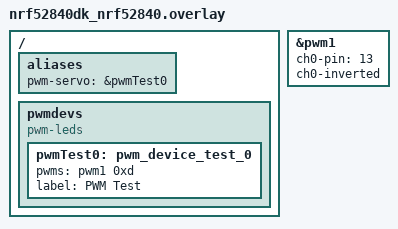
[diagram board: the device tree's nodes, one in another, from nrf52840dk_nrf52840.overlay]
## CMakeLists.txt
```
#
# Copyright (c) 2019 Nordic Semiconductor ASA
#
# SPDX-License-Identifier: LicenseRef-BSD-5-Clause-Nordic
#
cmake_minimum_required(VERSION 3.8.2)

#Board selection
set(BOARD nrf52840dk_nrf52840)
#set(BOARD nrf5340pdk_nrf5340_cpunet)
#set(BOARD nrf5340pdk_nrf5340_cpuapp)
#set(BOARD nrf52840dongle_nrf52840)
#set(BOARD nrf52840dk_nrf52811)

find_package(Zephyr REQUIRED HINTS $ENV{ZEPHYR_BASE})
project(NONE)

# Include all files in folder src
FILE(GLOB app_sources_c src/*.c)
FILE(GLOB app_sources_cpp src/*.cpp)


target_sources(app PRIVATE
	${app_sources_c}
	${app_sources_cpp})
target_include_directories(app PRIVATE include)
```

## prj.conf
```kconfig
#
# Copyright (c) 2019 Nordic Semiconductor ASA
#
# SPDX-License-Identifier: LicenseRef-BSD-5-Clause-Nordic
#
CONFIG_NCS_SAMPLES_DEFAULTS=y

# General configuration
CONFIG_SYSTEM_WORKQUEUE_STACK_SIZE=2048
CONFIG_FLASH=y
CONFIG_FLASH_MAP=y
CONFIG_FCB=y
CONFIG_SETTINGS=y
CONFIG_HWINFO=y
CONFIG_LOG=y
CONFIG_LOG_PRINTK=y

CONFIG_DK_LIBRARY=y
CONFIG_BT_MESH_DK_PROV=y

# Bluetooth configuration
CONFIG_BT=y
CONFIG_BT_COMPANY_ID=0x0059
CONFIG_BT_DEVICE_NAME="Servo Valve"
CONFIG_BT_L2CAP_TX_MTU=69
CONFIG_BT_L2CAP_TX_BUF_COUNT=8
CONFIG_BT_LL_SW_SPLIT=y
CONFIG_BT_OBSERVER=y
CONFIG_BT_PERIPHERAL=y
CONFIG_BT_SETTINGS=y
CONFIG_BT_MAX_CONN=3

# Disable unused Bluetooth features
CONFIG_BT_CTLR_DUP_FILTER_LEN=0
CONFIG_BT_CTLR_LE_ENC=n
CONFIG_BT_DATA_LEN_UPDATE=n
CONFIG_BT_PHY_UPDATE=n
CONFIG_BT_CTLR_CHAN_SEL_2=n
CONFIG_BT_CTLR_MIN_USED_CHAN=n
CONFIG_BT_CTLR_PRIVACY=n

# Bluetooth Mesh configuration standrad node configuration
CONFIG_BT_MESH=y
CONFIG_BT_MESH_ADV_BUF_COUNT=13
CONFIG_BT_MESH_TX_SEG_MAX=10
CONFIG_BT_MESH_PB_GATT=y
# Bluetooth Mesh Node Features Normal
CONFIG_BT_MESH_RELAY=y
CONFIG_BT_MESH_FRIEND=n
CONFIG_BT_MESH_FRIEND_LPN_COUNT=10
CONFIG_BT_MESH_GATT_PROXY=y
# Bluetooth Mesh Node Features LPN
#CONFIG_BT_MESH_RELAY=n
#CONFIG_BT_MESH_FRIEND=n
#CONFIG_BT_MESH_LOW_POWER=y
#CONFIG_BT_MESH_LPN_AUTO=y
#CONFIG_BT_MESH_LPN_AUTO_TIMEOUT=5
#600 = 60s
#CONFIG_BT_MESH_LPN_POLL_TIMEOUT=600
#CONFIG_BT_MESH_GATT_PROXY=n
# Power Managment Device -> Needed for LPN
#CONFIG_PM=y
#CONFIG_PM_DEVICE=y
#CONFIG_PM_DEVICE_RUNTIME=y
#CONFIG_PM_CPU_OPS=y
#CONFIG_SERIAL=n

# Bluetooth Mesh models
CONFIG_BT_MESH_ONOFF_SRV=y

# Servos PWM
CONFIG_PWM=y
CONFIG_PWM_LOG_LEVEL_DBG=y

#For Reset
CONFIG_REBOOT=y

#For nRF52 Dongle (enable if flashed over USB / Disable if FLashed over SWD)
CONFIG_BOARD_HAS_NRF5_BOOTLOADER=y
```

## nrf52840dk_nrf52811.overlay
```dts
/ {
     aliases {
             pwm-servo = &pwm0;
     };
};
```

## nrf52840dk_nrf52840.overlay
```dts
/ {
     aliases {
             pwm-servo = &pwmTest0;
     };
};

&pwm1 {
  status = "okay";
  ch0-pin = <13>;
  ch0-inverted;
 };

/ {
	pwmdevs {
		compatible = "pwm-leds";
		pwmTest0: pwm_device_test_0 {
			pwms = < &pwm1 0xd >;
			label = "PWM Test";
		};
	};
};
```

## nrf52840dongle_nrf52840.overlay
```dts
/ {
     aliases {
             pwm-servo = &pwmTest0;
     };
};

&pwm1 {
  status = "okay";
  ch0-pin = <15>;
  ch0-inverted;
 };

/ {
	pwmdevs {
		compatible = "pwm-leds";
		pwmTest0: pwm_device_test_0 {
			pwms = < &pwm1 0xf >;
			label = "PWM Test";
		};
	};
};
```

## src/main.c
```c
#include "bm_blemesh.h"
#include "bm_simple_buttons_and_leds.h"
#include <zephyr.h>
#include <bm_servo_valve.h>
#include <sys/reboot.h>



void reset(){
  printk("Reboot now!\n");
  sys_reboot(SYS_REBOOT_COLD);
}


/**@brief Function for application main entry.
 */
void main(void) {
  // Start Application
  printk("Starting Application...\n");
  // Init MAC Address
  uint32_t LSB_MAC_Address = NRF_FICR->DEVICEADDR[0];
  printk("Preprogrammed Randomly Static MAC-Address (LSB): 0x%x, %u \n", LSB_MAC_Address, LSB_MAC_Address);
  // Init Leds
  bm_init_leds();
  //Init Reset Buttons
  bm_init_buttons(reset);
  // Start Mesh Operation
  bm_blemesh_enable(); // Will return faster than the Stack is realy ready... keep on waiting in the transition.

  bm_init_servo();

}
```

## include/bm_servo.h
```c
#ifndef BM_SERVO_H
#define BM_SERVO_H

void bm_init_servo(void);

void do_test(void);


#endif
```

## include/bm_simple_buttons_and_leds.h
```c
/*
This file is part of Benchamrk-Shared-Library.

Benchamrk-Shared-Library is free software: you can redistribute it and/or modify
it under the terms of the GNU General Public License as published by
the Free Software Foundation, either version 3 of the License, or
(at your option) any later version.

Benchamrk-Shared-Library is distributed in the hope that it will be useful,
but WITHOUT ANY WARRANTY; without even the implied warranty of
MERCHANTABILITY or FITNESS FOR A PARTICULAR PURPOSE.  See the
GNU General Public License for more details.

You should have received a copy of the GNU General Public License
along with Benchamrk-Shared-Library.  If not, see <http://www.gnu.org/licenses/>.
*/

/* AUTHOR ZEPHYR_BLE_MESH  :   Raffael Anklin        */
/* AUTHOR NRF_SDK_ZIGBEE   :   Cyrill Horath        */


#ifdef __cplusplus
extern "C" {
#endif

#ifndef SIMPLE_BUTTONS_AND_LEDS_H
#define SIMPLE_BUTTONS_AND_LEDS_H


#include <zephyr.h>
#include <device.h>
#include <devicetree.h>
#include <devicetree_unfixed.h>
#include <drivers/gpio.h>
#include <sys/util.h>
#include <sys/slist.h>

/*
 * Devicetree helper macro which gets the 'flags' cell from a 'gpios'
 * property, or returns 0 if the property has no 'flags' cell.
 */

#define FLAGS_OR_ZERO(node)						\
	COND_CODE_1(DT_PHA_HAS_CELL(node, gpios, flags),		\
		    (DT_GPIO_FLAGS(node, gpios)),			\
		    (0))



/* The devicetree node identifier for the "led0" alias. */
#define LED0_NODE DT_ALIAS(led0)

#if DT_NODE_HAS_STATUS(LED0_NODE, okay)
#define LED0	DT_GPIO_LABEL(LED0_NODE, gpios)
#define PIN_LED0	DT_GPIO_PIN(LED0_NODE, gpios)
#if DT_PHA_HAS_CELL(LED0_NODE, gpios, flags)
#define FLAGS_LED0	DT_GPIO_FLAGS(LED0_NODE, gpios)
#endif
#else
/* A build error here means your board isn't set up to blink an LED. */
#error "Unsupported board: led0 devicetree alias is not defined"
#define LED0	""
#define PIN_LED0	0
#endif

#ifndef FLAGS_LED0
#define FLAGS_LED0	0
#endif

/* The devicetree node identifier for the "led1" alias. Is the RED LED on THe nRF52 Donlge*/
#define LED1_NODE DT_ALIAS(led1)

#if DT_NODE_HAS_STATUS(LED1_NODE, okay)
#define LED1	DT_GPIO_LABEL(LED1_NODE, gpios)
#define PIN_LED1	DT_GPIO_PIN(LED1_NODE, gpios)
#if DT_PHA_HAS_CELL(LED1_NODE, gpios, flags)
#define FLAGS_LED1	DT_GPIO_FLAGS(LED1_NODE, gpios)
#endif
#else
/* A build error here means your board isn't set up to blink an LED. */
#error "Unsupported board: led1 devicetree alias is not defined"
#define LED1	""
#define PIN_LED1	0
#endif

#ifndef FLAGS_LED1
#define FLAGS_LED1	0
#endif


/* The devicetree node identifier for the "led2" alias. Is the GREEN LED on THe nRF52 Donlge*/
#define LED2_NODE DT_ALIAS(led2)

#if DT_NODE_HAS_STATUS(LED2_NODE, okay)
#define LED2	DT_GPIO_LABEL(LED2_NODE, gpios)
#define PIN_LED2	DT_GPIO_PIN(LED2_NODE, gpios)
#if DT_PHA_HAS_CELL(LED2_NODE, gpios, flags)
#define FLAGS_LED2	DT_GPIO_FLAGS(LED2_NODE, gpios)
#endif
#else
/* A build error here means your board isn't set up to blink an LED. */
#error "Unsupported board: led2 devicetree alias is not defined"
#define LED2	""
#define PIN_LED2	0
#endif

#ifndef FLAGS_LED2
#define FLAGS_LED1	0
#endif

/* The devicetree node identifier for the "led3" alias. Is the BLUE LED on THe nRF52 Donlge*/
#define LED3_NODE DT_ALIAS(led3)

#if DT_NODE_HAS_STATUS(LED3_NODE, okay)
#define LED3	DT_GPIO_LABEL(LED3_NODE, gpios)
#define PIN_LED3	DT_GPIO_PIN(LED3_NODE, gpios)
#if DT_PHA_HAS_CELL(LED3_NODE, gpios, flags)
#define FLAGS_LED3	DT_GPIO_FLAGS(LED3_NODE, gpios)
#endif
#else
/* A build error here means your board isn't set up to blink an LED. */
#error "Unsupported board: led3 devicetree alias is not defined"
#define LED3	""
#define PIN_LED3	0
#endif

#ifndef FLAGS_LED3
#define FLAGS_LED3	0
#endif


/*
 * Get button configuration from the devicetree sw0 alias.
 *
 * At least a GPIO device and pin number must be provided. The 'flags'
 * cell is optional.
 */

#define SW0_NODE	DT_ALIAS(sw0)

#if DT_NODE_HAS_STATUS(SW0_NODE, okay)
#define SW0_GPIO_LABEL	DT_GPIO_LABEL(SW0_NODE, gpios)
#define SW0_GPIO_PIN	DT_GPIO_PIN(SW0_NODE, gpios)
#define SW0_GPIO_FLAGS	(GPIO_INPUT | FLAGS_OR_ZERO(SW0_NODE) | GPIO_INT_DEBOUNCE)
#else
#error "Unsupported board: sw0 devicetree alias is not defined"
#define SW0_GPIO_LABEL	""
#define SW0_GPIO_PIN	0
#define SW0_GPIO_FLAGS	0
#endif




/**
* Init the Buttons
*
*/
void bm_init_buttons(void (*button0_cb)());



/**
* Get the BUTTON0 Toggled State
*
* @return State of the BUTTON0 Toggled State (0/1)
*/
bool bm_button0_toggle_state_get();

/**
* Set the BUTTON0 Toggled State
*
* @param State of the BUTTON0 Toggled State (0/1)
*/
void bm_button0_toggle_state_set(bool newstate);



/**
* Init the Leds
*
*/
void bm_init_leds();

/**
* Set the LED0 State
*
* @param State to set the LED0 to (0/1) (GREEN no RGB on nRF52 Dongle / LED1 on nRF52 DK)
*/
void bm_led0_set(bool state);

/**
* Get the LED0 State
*
* @return State of the LED0 (0/1) (GREEN no RGB on nRF52 Dongle / LED1 on nRF52 DK)
*/
bool bm_led0_get();


/**
* Set the LED1 State
*
* @param State to set the LED1 to (0/1) (RED on nRF52 Dongle / LED2 on nRF52 DK)
*/
void bm_led1_set(bool state);

/**
* Get the LED1 State
*
* @return State of the LED1 (0/1) (RED on nRF52 Dongle / LED2 on nRF52 DK)
*/
bool bm_led1_get();

/**
* Set the LED2 State
*
* @param State to set the LED2 to (0/1) (GREEN on nRF52 Dongle / LED3 on nRF52 DK)
*/
void bm_led2_set(bool state);

/**
* Get the LED2 State
*
* @return State of the LED2 (0/1) (GREEN on nRF52 Dongle / LED3 on nRF52 DK)
*/
bool bm_led2_get();

/**
* Set the LED3 State
*
* @param State to set the LED3 to (0/1) (BLUE on nRF52 Dongle / LED4 on nRF52 DK)
*/
void bm_led3_set(bool state);

/**
* Get the LED3 State
*
* @return State of the LED3 (0/1) (BLUE on nRF52 Dongle / LED4 on nRF52 DK)
*/
bool bm_led3_get();


#endif

#ifdef __cplusplus
}
#endif
```

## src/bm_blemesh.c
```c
/*
This file is part of Bluetooth-Benchamrk.

Bluetooth-Benchamrk is free software: you can redistribute it and/or modify
it under the terms of the GNU General Public License as published by
the Free Software Foundation, either version 3 of the License, or
(at your option) any later version.

Bluetooth-Benchamrk is distributed in the hope that it will be useful,
but WITHOUT ANY WARRANTY; without even the implied warranty of
MERCHANTABILITY or FITNESS FOR A PARTICULAR PURPOSE.  See the
GNU General Public License for more details.

You should have received a copy of the GNU General Public License
along with Bluetooth-Benchamrk.  If not, see <http://www.gnu.org/licenses/>.
*/

/* AUTHOR 	 :    Raffael Anklin       */

/* Pin Assigments: 

| Port.Pin 	| Description
|	P1.10	|	Switch ON/OFF
|	P1.13	|	Signal from Host (1=ON/0=OFF)
|	P1.15	|	Switch Pulse from Host (1s High for Active Switching)

*/


#include <bluetooth/bluetooth.h>
#include <bluetooth/mesh/models.h>
#include <drivers/hwinfo.h>
#include "bm_blemesh_model_handler.h"
#include "bm_blemesh.h"
#include <bluetooth/mesh/main.h>
#include "bm_simple_buttons_and_leds.h"



static bool initialized=false; // Flag if the Stack is initialized

static void prov_complete(uint16_t net_idx, uint16_t src)
{
	printk("Prov complete! Addr: 0x%04x\n", src);
}

static void prov_reset(void)
{
	bt_mesh_prov_enable(BT_MESH_PROV_ADV | BT_MESH_PROV_GATT);
}

static int input(bt_mesh_input_action_t act, uint8_t size)
{
	printk("Press a button to set the right number.");
	return 0;
}

static void input_complete(void)
{
	printk("Input Complete");
}

static int output_number(bt_mesh_output_action_t action, uint32_t number)
{
	if (action == BT_MESH_DISPLAY_NUMBER) {
		printk("OOB Number: %u\n", number);
		return 0;
	}

	if (action == BT_MESH_BLINK) {
		printk("Blinking %u times", number);
		return 0;
	}

	return -ENOTSUP;
}

static int output_string(const char *string)
{
	printk("OOB String: %s\n", string);
	return 0;
}

static uint8_t dev_uuid[16];

static struct bt_mesh_prov prov = {
	.uuid = dev_uuid,
	.output_size = 1,
	.output_actions = (0),
	.output_number = output_number,
	.output_string = output_string,
	.input_size = 1,
	.input = input,
	.complete = prov_complete,
	.input_complete = input_complete,
	.reset = prov_reset
	};

// Init the rest while Bluetooth is enabled
static void bt_ready(int err){

	/* --------------- Init Board ------------*/
	printk("Init Buttons and LEDs...\n");
	
	printk("Buttons and LEDs initialized\n");
	/* ===================================*/
	
	/* --------------- Init Mesh ------------*/
	printk("Init Mesh...\n");
	
	hwinfo_get_device_id(dev_uuid, sizeof(dev_uuid));
	// Do catch for nrf53 -> no HWINFO set (0xFFFF)
	if (dev_uuid[0] == 0xFF && dev_uuid[1] == 0xFF && dev_uuid[5] == 0xFF){
		uint8_t *p0 = (uint8_t*)&NRF_FICR->DEVICEADDR[0]; // Use MAC Address for UUID
		dev_uuid[0] = p0[0];
		dev_uuid[1] = p0[1];
		dev_uuid[2] = p0[2];
		dev_uuid[3] = p0[3];
		uint8_t *p1 = (uint8_t*)&NRF_FICR->DEVICEADDR[1]; // Use MAC Address for UUID
		dev_uuid[4] = p1[0];
		dev_uuid[5] = p1[1];
	}

	err = bt_mesh_init(&prov, bm_blemesh_model_handler_init());
	if (err)
	{
		printk("Initializing mesh failed (err %d)\n", err);
		return;
	}
	printk("Mesh initialized\n");
	/* ===================================*/

	/* ------------- Provisioning ------------*/
	printk("Provisioning...\n");
	if (IS_ENABLED(CONFIG_SETTINGS))
	{
		settings_load();
	}
	/* 
	err = bt_mesh_provision(net_key, net_idx, flags, iv_index, addr,
							dev_key);
	*/
	/* This will be a no-op if settings_load() loaded provisioning info */
	err = bt_mesh_prov_enable(BT_MESH_PROV_ADV | BT_MESH_PROV_GATT);
	if (err == -EALREADY)
	{
		printk("Already Provisioned (Restored Settings)\n");
	}
	else if (err)
	{
		printk("Provisioning failed (err %d)\n", err);
		return;
	}
	else
	{
		printk("Provisioning completed\n");
	}
	/* ===================================*/

	initialized = true;
}

void bm_blemesh_enable(void)
{
	int err;

	/* ---------- Init Bluetooth ---------- */
	printk("Enabling Bluetooth...\n");
	err = bt_enable(bt_ready);
	while (initialized == false){
		k_sleep(K_MSEC(10));
	}
	if (err)
	{
		printk("Bluetooth init failed (err %d)\n", err);
		return;
	} 
	printk("Bluetooth initialized\n");
	/* =====================================*/

	
	//bm_sleep(bm_rand_32 % 5000); // Sleep Random Time for LPN Activation
	/*
	bt_mesh_cfg_friend_set(net_idx,addr,false,&stat);
	printk("Err Code: %d\n", stat);
	bt_mesh_lpn_set(true); // Enable Low Power Node
	*/	
	printk("Configuring done\n");

	//bm_led0_set(true); // Signal that the Configuring was sucessfull
	/* ===================================*/	
}
```

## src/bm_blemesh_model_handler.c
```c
/*
This file is part of Bluetooth-Benchamrk.

Bluetooth-Benchamrk is free software: you can redistribute it and/or modify
it under the terms of the GNU General Public License as published by
the Free Software Foundation, either version 3 of the License, or
(at your option) any later version.

Bluetooth-Benchamrk is distributed in the hope that it will be useful,
but WITHOUT ANY WARRANTY; without even the implied warranty of
MERCHANTABILITY or FITNESS FOR A PARTICULAR PURPOSE.  See the
GNU General Public License for more details.

You should have received a copy of the GNU General Public License
along with Bluetooth-Benchamrk.  If not, see <http://www.gnu.org/licenses/>.
*/

/* AUTHOR 	 :    Raffael Anklin       */


#include "bm_simple_buttons_and_leds.h"
#include "bm_blemesh.h"
#include "bm_blemesh_model_handler.h"

#include <bluetooth/bluetooth.h>
#include <bluetooth/mesh/models.h>
#include <bluetooth/mesh/model_types.h>




/** ON/OFF Server definition */
static void valve_set(struct bt_mesh_onoff_srv *srv, struct bt_mesh_msg_ctx *ctx,
					const struct bt_mesh_onoff_set *set,
					struct bt_mesh_onoff_status *rsp)
{
	// Set DK LED index
	//bm_switch_set(set->on_off);
}

static void valve_get(struct bt_mesh_onoff_srv *srv, struct bt_mesh_msg_ctx *ctx,
					struct bt_mesh_onoff_status *rsp)
{
	// Send respond Status
	//rsp->present_on_off = bm_switch_get();
}

static const struct bt_mesh_onoff_srv_handlers onoff_handlers = {
	.set = valve_set,
	.get = valve_get,
};

static struct bt_mesh_onoff_srv on_off_srv = BT_MESH_ONOFF_SRV_INIT(&onoff_handlers);

/** Health Server definition */
static void attention_on(struct bt_mesh_model *model)
{
	printk("attention_on()\n");
}

static void attention_off(struct bt_mesh_model *model)
{
	printk("attention_off()\n");
}
static const struct bt_mesh_health_srv_cb health_srv_cb = {
	.attn_on = attention_on,
	.attn_off = attention_off,
};

static struct bt_mesh_health_srv health_srv = {
	.cb = &health_srv_cb,
};

BT_MESH_HEALTH_PUB_DEFINE(health_pub, 0);

/* Define all Elements */
static struct bt_mesh_elem elements[] = {
	BT_MESH_ELEM(
		1, BT_MESH_MODEL_LIST(BT_MESH_MODEL_CFG_SRV, BT_MESH_MODEL_HEALTH_SRV(&health_srv, &health_pub), BT_MESH_MODEL_ONOFF_SRV(&on_off_srv)),
		BT_MESH_MODEL_NONE)};

/* Create Composition */
static const struct bt_mesh_comp comp = {
	.cid = CONFIG_BT_COMPANY_ID,
	.elem = elements,
	.elem_count = ARRAY_SIZE(elements),
};

const struct bt_mesh_comp *bm_blemesh_model_handler_init(void)
{
	return &comp;
}
```

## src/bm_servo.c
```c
/*
 * Copyright (c) 2016 Intel Corporation
 * Copyright (c) 2020 Nordic Semiconductor ASA
 *
 * SPDX-License-Identifier: Apache-2.0
 */

/**
 * @file Sample app to demonstrate PWM.
 */

#include <zephyr.h>
#include <sys/printk.h>
#include <device.h>
#include <drivers/pwm.h>

#define PWM_LED0_NODE	DT_ALIAS(pwm_servo)

#if DT_NODE_HAS_STATUS(PWM_LED0_NODE, okay)
#define PWM_CTLR	DT_PWMS_CTLR(PWM_LED0_NODE)
#define PWM_CHANNEL	DT_PWMS_CHANNEL(PWM_LED0_NODE)
#else
#error "Unsupported board: pwm-led0 devicetree alias is not defined"
#define PWM_CTLR	DT_INVALID_NODE
#define PWM_CHANNEL	0
#define PWM_FLAGS	0
#endif



#define PERIOD_USEC	(20U * USEC_PER_MSEC)
#define STEP_USEC	10
#define CLOSED_PULSE_USEC	(177U * 100)
#define OPEND_PULSE_USEC	(187U * 100)

enum direction {
	CLOSED,
	OPEND,
};

const struct device *pwm;

void bm_init_servo(void){

    	pwm = DEVICE_DT_GET(PWM_CTLR);
	if (!device_is_ready(pwm)) {
		printk("Error: PWM device %s is not ready\n", pwm->name);
		return;
	}

}

void do_test(void)
{
    uint32_t pulse_width = CLOSED_PULSE_USEC;
	enum direction dir = CLOSED;
	int ret;
	while (1) {
		ret = pwm_pin_set_usec(pwm, PWM_CHANNEL, PERIOD_USEC, pulse_width, 0);
		if (ret < 0) {
			printk("Error %d: failed to set pulse width\n", ret);
			return;
		}

		if (dir == CLOSED) {
            pulse_width = OPEND_PULSE_USEC;
            dir = OPEND;
		} else {
            pulse_width = CLOSED_PULSE_USEC;
            dir = CLOSED;

		}

		k_sleep(K_SECONDS(3));
	}
}
```

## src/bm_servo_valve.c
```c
/*
 * Copyright (c) 2016 Intel Corporation
 * Copyright (c) 2020 Nordic Semiconductor ASA
 *
 * SPDX-License-Identifier: Apache-2.0
 */

/**
 * @file Sample app to demonstrate PWM.
 */

#include <zephyr.h>
#include <sys/printk.h>
#include <device.h>
#include <drivers/pwm.h>
#include <bm_simple_buttons_and_leds.h>

#define PWM_LED0_NODE	DT_ALIAS(pwm_servo)

#if DT_NODE_HAS_STATUS(PWM_LED0_NODE, okay)
#define PWM_CTLR	DT_PWMS_CTLR(PWM_LED0_NODE)
#define PWM_CHANNEL	DT_PWMS_CHANNEL(PWM_LED0_NODE)
#else
#error "Unsupported board: pwm-led0 devicetree alias is not defined"
#define PWM_CTLR	DT_INVALID_NODE
#define PWM_CHANNEL	0
#define PWM_FLAGS	0
#endif



#define PERIOD_USEC	(20U * USEC_PER_MSEC)
#define STEP_USEC	10
#define CLOSED_PULSE_USEC	(177U * 100)
#define OPEND_PULSE_USEC	(187U * 100)

enum direction {
	CLOSED,
	OPEND,
};

const struct device *pwm;

bool bm_status_servo_valve;


static struct k_work_delayable leds_off_work;

static void do_leds_off()
{
	bm_led0_set(false);
	bm_led1_set(false);
	bm_led2_set(false);
	bm_led3_set(false);
}

static void leds_off(struct k_work *work)
{
	do_leds_off();
}


void bm_init_servo(void){

    	pwm = DEVICE_DT_GET(PWM_CTLR);
	if (!device_is_ready(pwm)) {
		printk("Error: PWM device %s is not ready\n", pwm->name);
		return;
	}	
	/* initialize work item for turning LEDS OFF */
	k_work_init_delayable(&leds_off_work, leds_off);
	do_leds_off();
	bm_led3_set(true);
	k_work_reschedule(&leds_off_work, K_MSEC(60*1000));
}

void bm_open_servo_valve(void)
{
	static int ret;
	ret = pwm_pin_set_usec(pwm, PWM_CHANNEL, PERIOD_USEC, OPEND_PULSE_USEC, 0);
	if (ret < 0) {
		printk("Error %d: failed to set pulse width\n", ret);
		return;
	}
	bm_status_servo_valve = true;
	do_leds_off();
	bm_led2_set(true);
	k_work_reschedule(&leds_off_work, K_MSEC(60*1000));
}

void bm_close_servo_valve(void)
{
	static int ret;
	ret = pwm_pin_set_usec(pwm, PWM_CHANNEL, PERIOD_USEC, CLOSED_PULSE_USEC, 0);
	if (ret < 0) {
		printk("Error %d: failed to set pulse width\n", ret);
		return;
	}
	bm_status_servo_valve = false;
	do_leds_off();
	bm_led1_set(true);
	k_work_reschedule(&leds_off_work, K_MSEC(60*1000));
}
```

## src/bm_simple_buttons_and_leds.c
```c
/*
This file is part of Benchmark-Shared-Library.

Benchmark-Shared-Library is free software: you can redistribute it and/or modify
it under the terms of the GNU General Public License as published by
the Free Software Foundation, either version 3 of the License, or
(at your option) any later version.

Benchmark-Shared-Library is distributed in the hope that it will be useful,
but WITHOUT ANY WARRANTY; without even the implied warranty of
MERCHANTABILITY or FITNESS FOR A PARTICULAR PURPOSE.  See the
GNU General Public License for more details.

You should have received a copy of the GNU General Public License
along with Benchmark-Shared-Library.  If not, see <http://www.gnu.org/licenses/>.
*/

/* AUTHOR ZEPHYR_BLE_MESH  :   Raffael Anklin        */
/* AUTHOR NRF_SDK_ZIGBEE   :   Cyrill Horath        */

#include "bm_simple_buttons_and_leds.h"


const struct device *dev_led0, *dev_led1, *dev_led2, *dev_led3, *dev_button0;
bool led0_is_on, led1_is_on, led2_is_on, led3_is_on = true;
bool button0_toggel_state = true;
int ret;

static struct gpio_callback button_cb_data;

static struct k_work_delayable buttons_debounce;

static void (*button0_callback)();

static void buttons_debounce_fn(struct k_work *work) {
  button0_toggel_state = !button0_toggel_state;
  button0_callback();
}


void button_pressed(const struct device *port,
					struct gpio_callback *cb,
					gpio_port_pins_t pins) {
  if (port == dev_button0) {
    k_work_reschedule(&buttons_debounce, K_MSEC(170)); // Debounce the Button
                                                           //button0_callback();
  }
  //printk("Button pressed at %" PRIu32 "\n", k_cycle_get_32());
}

gpio_callback_handler_t button_pressed_handler = &button_pressed;


/* Init the Buttons */
void bm_init_buttons(void (*button0_cb)()) {
  dev_button0 = device_get_binding(SW0_GPIO_LABEL);
  if (dev_button0 == NULL) {
    printk("Error: didn't find %s device\n", SW0_GPIO_LABEL);
    return;
  }
  ret = gpio_pin_configure(dev_button0, SW0_GPIO_PIN, SW0_GPIO_FLAGS);
  if (ret != 0) {
    printk("Error %d: failed to configure %s pin %d\n",
        ret, SW0_GPIO_LABEL, SW0_GPIO_PIN);
    return;
  }
  ret = gpio_pin_interrupt_configure(dev_button0,
      SW0_GPIO_PIN,
      GPIO_INT_EDGE_TO_ACTIVE);
  if (ret != 0) {
    printk("Error %d: failed to configure interrupt on %s pin %d\n",
        ret, SW0_GPIO_LABEL, SW0_GPIO_PIN);
    return;
  }

  gpio_init_callback(&button_cb_data, button_pressed_handler, BIT(SW0_GPIO_PIN));
  gpio_add_callback(dev_button0, &button_cb_data);
  printk("Set up button at %s pin %d\n", SW0_GPIO_LABEL, SW0_GPIO_PIN);
  button0_callback = button0_cb;

  k_work_init_delayable(&buttons_debounce, buttons_debounce_fn);
}



/* Init the Leds */
void bm_init_leds() {
  dev_led0 = device_get_binding(LED0);
  if (dev_led0 == NULL) {
    printk("Error no LED0 found");
    return;
  }
  ret = gpio_pin_configure(dev_led0, PIN_LED0, GPIO_OUTPUT_INACTIVE | FLAGS_LED0);
  if (ret < 0) {
    printk("Error in configuration of led0 pin (err %d)", ret);
    return;
  }
  dev_led1 = device_get_binding(LED1);
  if (dev_led1 == NULL) {
    printk("Error no LED1 found");
    return;
  }
  ret = gpio_pin_configure(dev_led1, PIN_LED1, GPIO_OUTPUT_INACTIVE | FLAGS_LED1);
  if (ret < 0) {
    printk("Error in configuration of led1 pin (err %d)", ret);
    return;
  }
  dev_led2 = device_get_binding(LED2);
  if (dev_led2 == NULL) {
    printk("Error no LED2 found");
    return;
  }
  ret = gpio_pin_configure(dev_led2, PIN_LED2, GPIO_OUTPUT_INACTIVE | FLAGS_LED2);
  if (ret < 0) {
    printk("Error in configuration of led2 pin (err %d)", ret);
    return;
  }
  dev_led3 = device_get_binding(LED3);
  if (dev_led3 == NULL) {
    printk("Error no LED3 found");
    return;
  }
  ret = gpio_pin_configure(dev_led3, PIN_LED3, GPIO_OUTPUT_INACTIVE | FLAGS_LED3);
  if (ret < 0) {
    printk("Error in configuration of led3 pin (err %d)", ret);
    return;
  }
}


/* Set LED0. pca10059 -> Green LED */
void bm_led0_set(bool state) {
  gpio_pin_set(dev_led0, PIN_LED0, (int)state);
  led0_is_on = state;
}

/* Get LED0 */
bool bm_led0_get() {
  return led0_is_on;
}

/* Set LED1. pca10059 -> Red LED (RGB) */
void bm_led1_set(bool state) {
  gpio_pin_set(dev_led1, PIN_LED1, (int)state);
  led1_is_on = state;
}

/* Get LED1 */
bool bm_led1_get() {
  return led1_is_on;
}

/* Set LED2. pca10059 -> Green LED (RGB) */
void bm_led2_set(bool state) {
  gpio_pin_set(dev_led2, PIN_LED2, (int)state);
  led2_is_on = state;
}

/* Get LED2 */
bool bm_led2_get() {
  return led2_is_on;
}

/* Set LED3. pca10059 -> Blue LED (RGB)  */
void bm_led3_set(bool state) {
  gpio_pin_set(dev_led3, PIN_LED3, (int)state);
  led3_is_on = state;
}

/* Get LED3 */
bool bm_led3_get() {
  return led3_is_on;
}


/* Get BUTTON0 Toggled State*/
bool bm_button0_toggle_state_get() {
  //gpio_pin_get(dev_led0, PIN_LED0, (int)state);
  return button0_toggel_state;
}

/* Set BUTTON0 Toggled State*/
void bm_button0_toggle_state_set(bool newstate) {
  //gpio_pin_get(dev_led0, PIN_LED0, (int)state);
  button0_toggel_state = newstate;
}
```
